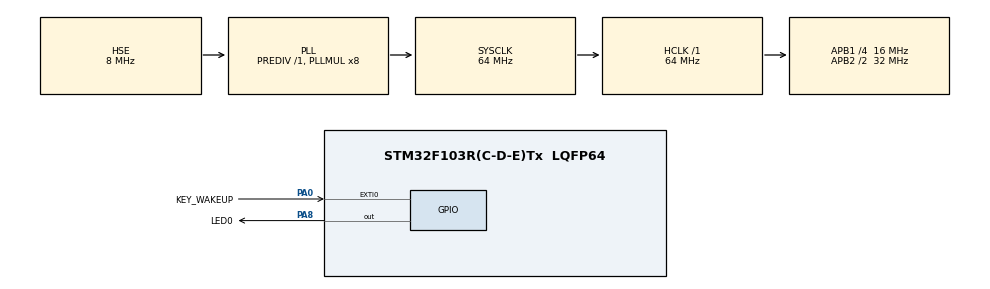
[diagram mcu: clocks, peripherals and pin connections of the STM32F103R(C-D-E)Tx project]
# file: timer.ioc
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Mcu.Family=STM32F1
Mcu.Name=STM32F103R(C-D-E)Tx
Mcu.Package=LQFP64
NVIC.EXTI0_IRQn=true\:1\:1\:true\:false\:true\:true\:true\:true
NVIC.PriorityGroup=NVIC_PRIORITYGROUP_2
NVIC.TIM3_IRQn=true\:1\:0\:true\:false\:true\:true\:true\:true
PA0-WKUP.GPIO_Label=KEY_WAKEUP
PA0-WKUP.GPIO_ModeDefaultEXTI=GPIO_MODE_IT_FALLING
PA0-WKUP.Signal=GPXTI0
PA13.Mode=Serial_Wire
PA13.Signal=SYS_JTMS-SWDIO
PA14.Mode=Serial_Wire
PA14.Signal=SYS_JTCK-SWCLK
PA8.GPIO_Label=LED0
PA8.GPIO_ModeDefaultOutputPP=GPIO_MODE_OUTPUT_PP
PA8.GPIO_PuPd=GPIO_NOPULL
PA8.GPIO_Speed=GPIO_SPEED_FREQ_HIGH
PA8.Signal=GPIO_Output
PD0-OSC_IN.Mode=HSE-External-Oscillator
PD0-OSC_IN.Signal=RCC_OSC_IN
PD1-OSC_OUT.Mode=HSE-External-Oscillator
PD1-OSC_OUT.Signal=RCC_OSC_OUT
ProjectManager.HeapSize=0x200
ProjectManager.StackSize=0x400
ProjectManager.TargetToolchain=CMake
RCC.AHBFreq_Value=64000000
RCC.APB1CLKDivider=RCC_HCLK_DIV4
RCC.APB1Freq_Value=16000000
RCC.APB1TimFreq_Value=32000000
RCC.APB2CLKDivider=RCC_HCLK_DIV2
RCC.APB2Freq_Value=32000000
RCC.APB2TimFreq_Value=64000000
RCC.HCLKFreq_Value=64000000
RCC.PLLMUL=RCC_PLL_MUL8
RCC.PLLSourceVirtual=RCC_PLLSOURCE_HSE
RCC.SYSCLKFreq_VALUE=64000000
RCC.SYSCLKSource=RCC_SYSCLKSOURCE_PLLCLK
RCC.USBFreq_Value=64000000
TIM3.Period=999
TIM3.Prescaler=15999
VP_TIM3_VS_ClockSourceINT.Mode=Internal
board=custom

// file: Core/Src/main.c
/* USER CODE BEGIN Header */
/**
 ******************************************************************************
 * @file           : main.c
 * @brief          : Main program body
 ******************************************************************************
 * @attention
 *
 * Copyright (c) 2024 STMicroelectronics.
 * All rights reserved.
 *
 * This software is licensed under terms that can be found in the LICENSE file
 * in the root directory of this software component.
 * If no LICENSE file comes with this software, it is provided AS-IS.
 *
 ******************************************************************************
 */
/* USER CODE END Header */
#include "main.h"
#include "tim.h"
#include "gpio.h"

/* USER CODE BEGIN Includes */
#include "lcd.h"
#include "stm32f1xx_it.h"
/* USER CODE END Includes */

/* USER CODE BEGIN PV */
extern uint16_t countNumber;
extern uint8_t msgString[22];
/* USER CODE END PV */

void SystemClock_Config(void);

int main(void)
{

  /* MCU Configuration--------------------------------------------------------*/

  /* Reset of all peripherals, Initializes the Flash interface and the Systick. */
  HAL_Init();

  /* Configure the system clock */
  SystemClock_Config();

  /* Initialize all configured peripherals */
  MX_GPIO_Init();
  MX_TIM3_Init();
  /* USER CODE BEGIN 2 */
  LCD_Init();
  HAL_TIM_Base_Start_IT(&htim3);
  countNumber = 0;
  /* USER CODE END 2 */

  /* Infinite loop */
  /* USER CODE BEGIN WHILE */
  LCD_Clear(WHITE);
  BACK_COLOR = WHITE;
  POINT_COLOR = BLACK;
  while (1) {
    /* USER CODE END WHILE */

    /* USER CODE BEGIN 3 */
    LCD_ShowString(30, 40, 200, 12, 12, msgString);
  }
  /* USER CODE END 3 */
}

void SystemClock_Config(void)
{
  RCC_OscInitTypeDef RCC_OscInitStruct = {0};
  RCC_ClkInitTypeDef RCC_ClkInitStruct = {0};

  /** Initializes the RCC Oscillators according to the specified parameters
  * in the RCC_OscInitTypeDef structure.
  */
  RCC_OscInitStruct.OscillatorType = RCC_OSCILLATORTYPE_HSE;
  RCC_OscInitStruct.HSEState = RCC_HSE_ON;
  RCC_OscInitStruct.HSEPredivValue = RCC_HSE_PREDIV_DIV1;
  RCC_OscInitStruct.HSIState = RCC_HSI_ON;
  RCC_OscInitStruct.PLL.PLLState = RCC_PLL_ON;
  RCC_OscInitStruct.PLL.PLLSource = RCC_PLLSOURCE_HSE;
  RCC_OscInitStruct.PLL.PLLMUL = RCC_PLL_MUL8;
  if (HAL_RCC_OscConfig(&RCC_OscInitStruct) != HAL_OK)
  {
    Error_Handler();
  }

  /** Initializes the CPU, AHB and APB buses clocks
  */
  RCC_ClkInitStruct.ClockType = RCC_CLOCKTYPE_HCLK|RCC_CLOCKTYPE_SYSCLK
                              |RCC_CLOCKTYPE_PCLK1|RCC_CLOCKTYPE_PCLK2;
  RCC_ClkInitStruct.SYSCLKSource = RCC_SYSCLKSOURCE_PLLCLK;
  RCC_ClkInitStruct.AHBCLKDivider = RCC_SYSCLK_DIV1;
  RCC_ClkInitStruct.APB1CLKDivider = RCC_HCLK_DIV4;
  RCC_ClkInitStruct.APB2CLKDivider = RCC_HCLK_DIV2;

  if (HAL_RCC_ClockConfig(&RCC_ClkInitStruct, FLASH_LATENCY_2) != HAL_OK)
  {
    Error_Handler();
  }
}

void Error_Handler(void)
{
  __disable_irq();
  while (1) {
  }
}
